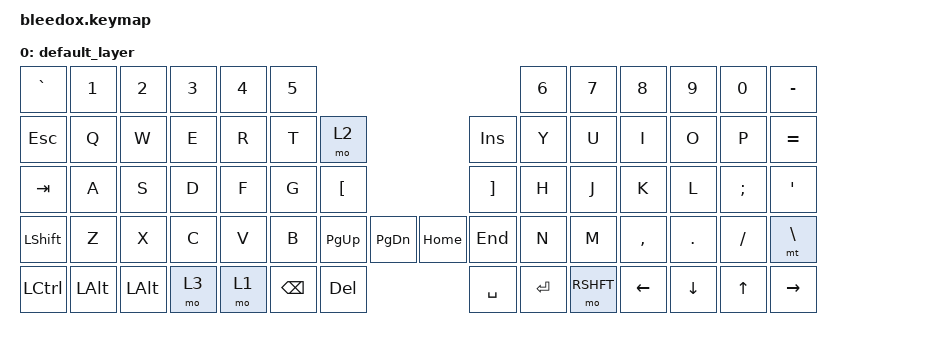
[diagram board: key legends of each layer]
#include <behaviors.dtsi>
#include <dt-bindings/zmk/keys.h>

/ {
    keymap {
        compatible =  "zmk,keymap" ;

        default_layer {
// ---------------------------------------------------------------------------------------------------------------------------
// | `     |  1   |  2  |   3   |  4  |  5  |                   ---                 |  6   |  7  |   8   |  9   | 0  |   -   |
// | ESC   |  Q   |  W  |   E   |  R  |  T  | RAISE |           ---         |  INS  |  Y   |  U  |   I   |  O   | P  |   =   |
// | TAB   |  A   |  S  |   D   |  F  |  G  |   [   |           ---         |  ]    |  H   |  J  |   K   |  L   | ;  |   '   |
// | SHIFT |  Z   |  X  |   C   |  V  |  B  | PG_UP | PG_DOWN | --- | HOME  | END   |  N   |  M  |   ,   |  .   | /  |   \   |
// | CTRL  | META | ALT | LOWER |   CODE    |  BKSP |   DEL   | --- | SPACE | ENTER |    SHIFT   | LEFT  | DOWN | UP | RIGHT |
            bindings = <
   &kp GRAVE &kp N1   &kp N2   &kp N3 &kp N4   &kp N5                                        &kp N6    &kp N7 &kp N8    &kp N9   &kp N0   &kp MINUS
   &kp ESC   &kp Q    &kp W    &kp E  &kp R    &kp T  &mo 2                         &kp INS  &kp Y     &kp U  &kp I     &kp O    &kp P    &kp EQUAL
   &kp TAB   &kp A    &kp S    &kp D  &kp F    &kp G  &kp LBKT                      &kp RBKT &kp H     &kp J  &kp K     &kp L    &kp SEMI &kp SQT
   &kp LSHFT &kp Z    &kp X    &kp C  &kp V    &kp B  &kp PG_UP &kp PG_DN &kp HOME  &kp END  &kp N     &kp M  &kp COMMA &kp DOT  &kp FSLH &mt BSLH
   &kp LCTRL &kp LALT &kp LALT &mo 3      &mo 1       &kp BSPC  &kp DEL   &kp SPACE &kp RET     &mo RSHFT     &kp LEFT  &kp DOWN &kp UP   &kp RIGHT
            >;

        };
    };
};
